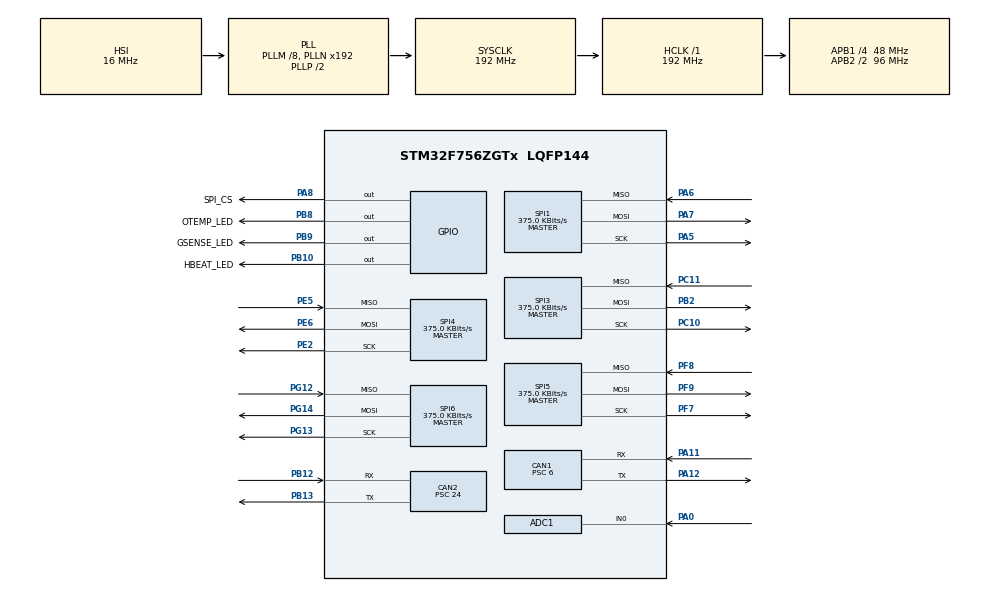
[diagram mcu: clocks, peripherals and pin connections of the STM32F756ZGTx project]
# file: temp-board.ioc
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ADC1.Channel-0\#ChannelRegularConversion=ADC_CHANNEL_0
ADC1.NbrOfConversionFlag=1
ADC1.Rank-0\#ChannelRegularConversion=1
ADC1.SamplingTime-0\#ChannelRegularConversion=ADC_SAMPLETIME_3CYCLES
ADC1.master=1
CAN1.ABOM=ENABLE
CAN1.AWUM=ENABLE
CAN1.BS1=CAN_BS1_6TQ
CAN1.BS2=CAN_BS2_1TQ
CAN1.CalculateBaudRate=1000000
CAN1.CalculateTimeBit=1000
CAN1.CalculateTimeQuantum=125.0
CAN1.Mode=CAN_MODE_LOOPBACK
CAN1.Prescaler=6
CAN2.ABOM=ENABLE
CAN2.AWUM=ENABLE
CAN2.BS1=CAN_BS1_6TQ
CAN2.BS2=CAN_BS2_1TQ
CAN2.CalculateBaudRate=250000
CAN2.CalculateTimeBit=4000
CAN2.CalculateTimeQuantum=500.0
CAN2.Prescaler=24
FREERTOS.Tasks01=taskMain_Loop,0,256,task_main_loop,Default,NULL,Dynamic,NULL,NULL;taskGCAN_TX,0,256,task_gcan_tx,Default,NULL,Dynamic,NULL,NULL;task_GCAN_RX,0,256,task_gcan_rx,Default,NULL,Dynamic,NULL,NULL
FREERTOS.configMINIMAL_STACK_SIZE=256
Mcu.Family=STM32F7
Mcu.Name=STM32F756ZGTx
Mcu.Package=LQFP144
NVIC.CAN1_RX0_IRQn=true\:5\:0\:false\:false\:true\:true\:true\:true\:true
NVIC.CAN1_RX1_IRQn=true\:5\:0\:false\:false\:true\:true\:true\:true\:true
NVIC.CAN1_TX_IRQn=true\:5\:0\:false\:false\:true\:true\:true\:true\:true
NVIC.PriorityGroup=NVIC_PRIORITYGROUP_4
NVIC.SPI1_IRQn=true\:5\:0\:false\:false\:true\:true\:true\:true\:true
NVIC.SPI3_IRQn=true\:5\:0\:false\:false\:true\:true\:true\:true\:true
NVIC.SPI4_IRQn=true\:5\:0\:false\:false\:true\:true\:true\:true\:true
NVIC.SPI5_IRQn=true\:5\:0\:false\:false\:true\:true\:true\:true\:true
NVIC.SPI6_IRQn=true\:5\:0\:false\:false\:true\:true\:true\:true\:true
NVIC.TIM6_DAC_IRQn=true\:0\:0\:false\:false\:true\:false\:false\:true\:true
NVIC.TIM8_TRG_COM_TIM14_IRQn=true\:5\:0\:false\:false\:true\:true\:true\:true\:true
NVIC.TimeBase=TIM6_DAC_IRQn
NVIC.TimeBaseIP=TIM6
PA0/WKUP.Signal=ADCx_IN0
PA11.Mode=CAN_Activate
PA11.Signal=CAN1_RX
PA12.Mode=CAN_Activate
PA12.Signal=CAN1_TX
PA5.Mode=Full_Duplex_Master
PA5.Signal=SPI1_SCK
PA6.Mode=Full_Duplex_Master
PA6.Signal=SPI1_MISO
PA7.Mode=Full_Duplex_Master
PA7.Signal=SPI1_MOSI
PA8.GPIO_Label=SPI_CS
PA8.Signal=GPIO_Output
PB10.GPIO_Label=HBEAT_LED
PB10.Signal=GPIO_Output
PB12.Mode=CAN_Activate
PB12.Signal=CAN2_RX
PB13.Mode=CAN_Activate
PB13.Signal=CAN2_TX
PB2.Mode=Full_Duplex_Master
PB2.Signal=SPI3_MOSI
PB8.GPIO_Label=OTEMP_LED
PB8.Signal=GPIO_Output
PB9.GPIO_Label=GSENSE_LED
PB9.Signal=GPIO_Output
PC10.Mode=Full_Duplex_Master
PC10.Signal=SPI3_SCK
PC11.Mode=Full_Duplex_Master
PC11.Signal=SPI3_MISO
PE2.Mode=Full_Duplex_Master
PE2.Signal=SPI4_SCK
PE5.Mode=Full_Duplex_Master
PE5.Signal=SPI4_MISO
PE6.Mode=Full_Duplex_Master
PE6.Signal=SPI4_MOSI
PF7.Mode=Full_Duplex_Master
PF7.Signal=SPI5_SCK
PF8.Mode=Full_Duplex_Master
PF8.Signal=SPI5_MISO
PF9.Mode=Full_Duplex_Master
PF9.Signal=SPI5_MOSI
PG12.Mode=Full_Duplex_Master
PG12.Signal=SPI6_MISO
PG13.Mode=Full_Duplex_Master
PG13.Signal=SPI6_SCK
PG14.Mode=Full_Duplex_Master
PG14.Signal=SPI6_MOSI
ProjectManager.HeapSize=0x200
ProjectManager.StackSize=0x400
ProjectManager.TargetToolchain=STM32CubeIDE
RCC.AHBFreq_Value=192000000
RCC.APB1CLKDivider=RCC_HCLK_DIV4
RCC.APB1Freq_Value=48000000
RCC.APB1TimFreq_Value=96000000
RCC.APB2CLKDivider=RCC_HCLK_DIV2
RCC.APB2Freq_Value=96000000
RCC.APB2TimFreq_Value=192000000
RCC.CortexFreq_Value=192000000
RCC.HCLKFreq_Value=192000000
RCC.HSE_VALUE=25000000
RCC.HSI_VALUE=16000000
RCC.LSE_VALUE=32768
RCC.PLLM=8
RCC.SYSCLKFreq_VALUE=192000000
RCC.SYSCLKSource=RCC_SYSCLKSOURCE_PLLCLK
RCC.USBFreq_Value=192000000
RCC.VCOOutputFreq_Value=384000000
SH.ADCx_IN0.0=ADC1_IN0,IN0
SPI1.BaudRatePrescaler=SPI_BAUDRATEPRESCALER_256
SPI1.CalculateBaudRate=375.0 KBits/s
SPI1.DataSize=SPI_DATASIZE_16BIT
SPI1.Direction=SPI_DIRECTION_2LINES
SPI1.FirstBit=SPI_FIRSTBIT_MSB
SPI1.Mode=SPI_MODE_MASTER
SPI1.NSSPMode=SPI_NSS_PULSE_DISABLE
SPI1.VirtualType=VM_MASTER
SPI3.BaudRatePrescaler=SPI_BAUDRATEPRESCALER_128
SPI3.CalculateBaudRate=375.0 KBits/s
SPI3.DataSize=SPI_DATASIZE_16BIT
SPI3.Direction=SPI_DIRECTION_2LINES
SPI3.Mode=SPI_MODE_MASTER
SPI3.NSSPMode=SPI_NSS_PULSE_DISABLE
SPI3.VirtualType=VM_MASTER
SPI4.BaudRatePrescaler=SPI_BAUDRATEPRESCALER_256
SPI4.CalculateBaudRate=375.0 KBits/s
SPI4.DataSize=SPI_DATASIZE_16BIT
SPI4.Direction=SPI_DIRECTION_2LINES
SPI4.Mode=SPI_MODE_MASTER
SPI4.NSSPMode=SPI_NSS_PULSE_DISABLE
SPI4.VirtualType=VM_MASTER
SPI5.BaudRatePrescaler=SPI_BAUDRATEPRESCALER_256
SPI5.CalculateBaudRate=375.0 KBits/s
SPI5.DataSize=SPI_DATASIZE_16BIT
SPI5.Direction=SPI_DIRECTION_2LINES
SPI5.Mode=SPI_MODE_MASTER
SPI5.NSSPMode=SPI_NSS_PULSE_DISABLE
SPI5.VirtualType=VM_MASTER
SPI6.BaudRatePrescaler=SPI_BAUDRATEPRESCALER_256
SPI6.CalculateBaudRate=375.0 KBits/s
SPI6.DataSize=SPI_DATASIZE_16BIT
SPI6.Direction=SPI_DIRECTION_2LINES
SPI6.Mode=SPI_MODE_MASTER
SPI6.NSSPMode=SPI_NSS_PULSE_DISABLE
SPI6.VirtualType=VM_MASTER
VP_FREERTOS_VS_CMSIS_V1.Mode=CMSIS_V1
VP_SYS_VS_tim6.Mode=TIM6
VP_TIM14_VS_ClockSourceINT.Mode=Enable_Timer
board=custom

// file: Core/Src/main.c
/* USER CODE BEGIN Header */
/**
  ******************************************************************************
  * @file           : main.c
  * @brief          : Main program body
  ******************************************************************************
  * @attention
  *
  * <h2><center>&copy; Copyright (c) 2021 STMicroelectronics.
  * All rights reserved.</center></h2>
  *
  * This software component is licensed by ST under BSD 3-Clause license,
  * the "License"; You may not use this file except in compliance with the
  * License. You may obtain a copy of the License at:
  *                        opensource.org/licenses/BSD-3-Clause
  *
  ******************************************************************************
  */
/* USER CODE END Header */
#include "main.h"
#include "cmsis_os.h"

/* USER CODE BEGIN Includes */
#include "temp_board_main.h"
#include "spi_adc.h"
#include "DAM.h"
/* USER CODE END Includes */

ADC_HandleTypeDef hadc1;

CAN_HandleTypeDef hcan1;
CAN_HandleTypeDef hcan2;

SPI_HandleTypeDef hspi1;
SPI_HandleTypeDef hspi3;
SPI_HandleTypeDef hspi4;
SPI_HandleTypeDef hspi5;
SPI_HandleTypeDef hspi6;

TIM_HandleTypeDef htim14;

osThreadId taskMain_LoopHandle;
osThreadId taskGCAN_TXHandle;
osThreadId task_GCAN_RXHandle;

void SystemClock_Config(void);
static void MX_GPIO_Init(void);
static void MX_CAN1_Init(void);
static void MX_CAN2_Init(void);
static void MX_SPI1_Init(void);
static void MX_SPI3_Init(void);
static void MX_SPI4_Init(void);
static void MX_SPI5_Init(void);
static void MX_SPI6_Init(void);
static void MX_TIM14_Init(void);
static void MX_ADC1_Init(void);
void task_main_loop(void const * argument);
void task_gcan_tx(void const * argument);
void task_gcan_rx(void const * argument);

int main(void)
{

  /* MCU Configuration--------------------------------------------------------*/

  /* Reset of all peripherals, Initializes the Flash interface and the Systick. */
  HAL_Init();

  /* Configure the system clock */
  SystemClock_Config();

  /* Initialize all configured peripherals */
  MX_GPIO_Init();
  MX_CAN1_Init();
  MX_CAN2_Init();
  MX_SPI1_Init();
  MX_SPI3_Init();
  MX_SPI4_Init();
  MX_SPI5_Init();
  MX_SPI6_Init();
  MX_TIM14_Init();
  MX_ADC1_Init();
  /* USER CODE BEGIN 2 */

  init(&hcan1, &hcan2);

  /* USER CODE END 2 */

  /* Create the thread(s) */
  /* definition and creation of taskMain_Loop */
  osThreadDef(taskMain_Loop, task_main_loop, osPriorityNormal, 0, 256);
  taskMain_LoopHandle = osThreadCreate(osThread(taskMain_Loop), NULL);

  /* definition and creation of taskGCAN_TX */
  osThreadDef(taskGCAN_TX, task_gcan_tx, osPriorityNormal, 0, 256);
  taskGCAN_TXHandle = osThreadCreate(osThread(taskGCAN_TX), NULL);

  /* definition and creation of task_GCAN_RX */
  osThreadDef(task_GCAN_RX, task_gcan_rx, osPriorityNormal, 0, 256);
  task_GCAN_RXHandle = osThreadCreate(osThread(task_GCAN_RX), NULL);

  /* Start scheduler */
  osKernelStart();

  /* We should never get here as control is now taken by the scheduler */
  /* Infinite loop */
  while (1)
  {

  }
}

void SystemClock_Config(void)
{
  RCC_OscInitTypeDef RCC_OscInitStruct = {0};
  RCC_ClkInitTypeDef RCC_ClkInitStruct = {0};

  /** Configure the main internal regulator output voltage
  */
  __HAL_RCC_PWR_CLK_ENABLE();
  __HAL_PWR_VOLTAGESCALING_CONFIG(PWR_REGULATOR_VOLTAGE_SCALE1);
  /** Initializes the RCC Oscillators according to the specified parameters
  * in the RCC_OscInitTypeDef structure.
  */
  RCC_OscInitStruct.OscillatorType = RCC_OSCILLATORTYPE_HSI;
  RCC_OscInitStruct.HSIState = RCC_HSI_ON;
  RCC_OscInitStruct.HSICalibrationValue = RCC_HSICALIBRATION_DEFAULT;
  RCC_OscInitStruct.PLL.PLLState = RCC_PLL_ON;
  RCC_OscInitStruct.PLL.PLLSource = RCC_PLLSOURCE_HSI;
  RCC_OscInitStruct.PLL.PLLM = 8;
  RCC_OscInitStruct.PLL.PLLN = 192;
  RCC_OscInitStruct.PLL.PLLP = RCC_PLLP_DIV2;
  RCC_OscInitStruct.PLL.PLLQ = 2;
  if (HAL_RCC_OscConfig(&RCC_OscInitStruct) != HAL_OK)
  {
    Error_Handler();
  }
  /** Activate the Over-Drive mode
  */
  if (HAL_PWREx_EnableOverDrive() != HAL_OK)
  {
    Error_Handler();
  }
  /** Initializes the CPU, AHB and APB buses clocks
  */
  RCC_ClkInitStruct.ClockType = RCC_CLOCKTYPE_HCLK|RCC_CLOCKTYPE_SYSCLK
                              |RCC_CLOCKTYPE_PCLK1|RCC_CLOCKTYPE_PCLK2;
  RCC_ClkInitStruct.SYSCLKSource = RCC_SYSCLKSOURCE_PLLCLK;
  RCC_ClkInitStruct.AHBCLKDivider = RCC_SYSCLK_DIV1;
  RCC_ClkInitStruct.APB1CLKDivider = RCC_HCLK_DIV4;
  RCC_ClkInitStruct.APB2CLKDivider = RCC_HCLK_DIV2;

  if (HAL_RCC_ClockConfig(&RCC_ClkInitStruct, FLASH_LATENCY_6) != HAL_OK)
  {
    Error_Handler();
  }
}

static void MX_ADC1_Init(void)
{

  ADC_ChannelConfTypeDef sConfig = {0};

  /** Configure the global features of the ADC (Clock, Resolution, Data Alignment and number of conversion)
  */
  hadc1.Instance = ADC1;
  hadc1.Init.ClockPrescaler = ADC_CLOCK_SYNC_PCLK_DIV4;
  hadc1.Init.Resolution = ADC_RESOLUTION_12B;
  hadc1.Init.ScanConvMode = ADC_SCAN_DISABLE;
  hadc1.Init.ContinuousConvMode = DISABLE;
  hadc1.Init.DiscontinuousConvMode = DISABLE;
  hadc1.Init.ExternalTrigConvEdge = ADC_EXTERNALTRIGCONVEDGE_NONE;
  hadc1.Init.ExternalTrigConv = ADC_SOFTWARE_START;
  hadc1.Init.DataAlign = ADC_DATAALIGN_RIGHT;
  hadc1.Init.NbrOfConversion = 1;
  hadc1.Init.DMAContinuousRequests = DISABLE;
  hadc1.Init.EOCSelection = ADC_EOC_SINGLE_CONV;
  if (HAL_ADC_Init(&hadc1) != HAL_OK)
  {
    Error_Handler();
  }
  /** Configure for the selected ADC regular channel its corresponding rank in the sequencer and its sample time.
  */
  sConfig.Channel = ADC_CHANNEL_0;
  sConfig.Rank = ADC_REGULAR_RANK_1;
  sConfig.SamplingTime = ADC_SAMPLETIME_3CYCLES;
  if (HAL_ADC_ConfigChannel(&hadc1, &sConfig) != HAL_OK)
  {
    Error_Handler();
  }

}

static void MX_CAN1_Init(void)
{

  hcan1.Instance = CAN1;
  hcan1.Init.Prescaler = 6;
  hcan1.Init.Mode = CAN_MODE_LOOPBACK;
  hcan1.Init.SyncJumpWidth = CAN_SJW_1TQ;
  hcan1.Init.TimeSeg1 = CAN_BS1_6TQ;
  hcan1.Init.TimeSeg2 = CAN_BS2_1TQ;
  hcan1.Init.TimeTriggeredMode = DISABLE;
  hcan1.Init.AutoBusOff = ENABLE;
  hcan1.Init.AutoWakeUp = ENABLE;
  hcan1.Init.AutoRetransmission = DISABLE;
  hcan1.Init.ReceiveFifoLocked = DISABLE;
  hcan1.Init.TransmitFifoPriority = DISABLE;
  if (HAL_CAN_Init(&hcan1) != HAL_OK)
  {
    Error_Handler();
  }

}

static void MX_CAN2_Init(void)
{

  hcan2.Instance = CAN2;
  hcan2.Init.Prescaler = 24;
  hcan2.Init.Mode = CAN_MODE_NORMAL;
  hcan2.Init.SyncJumpWidth = CAN_SJW_1TQ;
  hcan2.Init.TimeSeg1 = CAN_BS1_6TQ;
  hcan2.Init.TimeSeg2 = CAN_BS2_1TQ;
  hcan2.Init.TimeTriggeredMode = DISABLE;
  hcan2.Init.AutoBusOff = ENABLE;
  hcan2.Init.AutoWakeUp = ENABLE;
  hcan2.Init.AutoRetransmission = DISABLE;
  hcan2.Init.ReceiveFifoLocked = DISABLE;
  hcan2.Init.TransmitFifoPriority = DISABLE;
  if (HAL_CAN_Init(&hcan2) != HAL_OK)
  {
    Error_Handler();
  }

}

static void MX_SPI1_Init(void)
{

  /* SPI1 parameter configuration*/
  hspi1.Instance = SPI1;
  hspi1.Init.Mode = SPI_MODE_MASTER;
  hspi1.Init.Direction = SPI_DIRECTION_2LINES;
  hspi1.Init.DataSize = SPI_DATASIZE_16BIT;
  hspi1.Init.CLKPolarity = SPI_POLARITY_LOW;
  hspi1.Init.CLKPhase = SPI_PHASE_1EDGE;
  hspi1.Init.NSS = SPI_NSS_SOFT;
  hspi1.Init.BaudRatePrescaler = SPI_BAUDRATEPRESCALER_256;
  hspi1.Init.FirstBit = SPI_FIRSTBIT_MSB;
  hspi1.Init.TIMode = SPI_TIMODE_DISABLE;
  hspi1.Init.CRCCalculation = SPI_CRCCALCULATION_DISABLE;
  hspi1.Init.CRCPolynomial = 7;
  hspi1.Init.CRCLength = SPI_CRC_LENGTH_DATASIZE;
  hspi1.Init.NSSPMode = SPI_NSS_PULSE_DISABLE;
  if (HAL_SPI_Init(&hspi1) != HAL_OK)
  {
    Error_Handler();
  }

}

static void MX_SPI3_Init(void)
{

  /* SPI3 parameter configuration*/
  hspi3.Instance = SPI3;
  hspi3.Init.Mode = SPI_MODE_MASTER;
  hspi3.Init.Direction = SPI_DIRECTION_2LINES;
  hspi3.Init.DataSize = SPI_DATASIZE_16BIT;
  hspi3.Init.CLKPolarity = SPI_POLARITY_LOW;
  hspi3.Init.CLKPhase = SPI_PHASE_1EDGE;
  hspi3.Init.NSS = SPI_NSS_SOFT;
  hspi3.Init.BaudRatePrescaler = SPI_BAUDRATEPRESCALER_128;
  hspi3.Init.FirstBit = SPI_FIRSTBIT_MSB;
  hspi3.Init.TIMode = SPI_TIMODE_DISABLE;
  hspi3.Init.CRCCalculation = SPI_CRCCALCULATION_DISABLE;
  hspi3.Init.CRCPolynomial = 7;
  hspi3.Init.CRCLength = SPI_CRC_LENGTH_DATASIZE;
  hspi3.Init.NSSPMode = SPI_NSS_PULSE_DISABLE;
  if (HAL_SPI_Init(&hspi3) != HAL_OK)
  {
    Error_Handler();
  }

}

static void MX_SPI4_Init(void)
{

  /* SPI4 parameter configuration*/
  hspi4.Instance = SPI4;
  hspi4.Init.Mode = SPI_MODE_MASTER;
  hspi4.Init.Direction = SPI_DIRECTION_2LINES;
  hspi4.Init.DataSize = SPI_DATASIZE_16BIT;
  hspi4.Init.CLKPolarity = SPI_POLARITY_LOW;
  hspi4.Init.CLKPhase = SPI_PHASE_1EDGE;
  hspi4.Init.NSS = SPI_NSS_SOFT;
  hspi4.Init.BaudRatePrescaler = SPI_BAUDRATEPRESCALER_256;
  hspi4.Init.FirstBit = SPI_FIRSTBIT_MSB;
  hspi4.Init.TIMode = SPI_TIMODE_DISABLE;
  hspi4.Init.CRCCalculation = SPI_CRCCALCULATION_DISABLE;
  hspi4.Init.CRCPolynomial = 7;
  hspi4.Init.CRCLength = SPI_CRC_LENGTH_DATASIZE;
  hspi4.Init.NSSPMode = SPI_NSS_PULSE_DISABLE;
  if (HAL_SPI_Init(&hspi4) != HAL_OK)
  {
    Error_Handler();
  }

}

static void MX_SPI5_Init(void)
{

  /* SPI5 parameter configuration*/
  hspi5.Instance = SPI5;
  hspi5.Init.Mode = SPI_MODE_MASTER;
  hspi5.Init.Direction = SPI_DIRECTION_2LINES;
  hspi5.Init.DataSize = SPI_DATASIZE_16BIT;
  hspi5.Init.CLKPolarity = SPI_POLARITY_LOW;
  hspi5.Init.CLKPhase = SPI_PHASE_1EDGE;
  hspi5.Init.NSS = SPI_NSS_SOFT;
  hspi5.Init.BaudRatePrescaler = SPI_BAUDRATEPRESCALER_256;
  hspi5.Init.FirstBit = SPI_FIRSTBIT_MSB;
  hspi5.Init.TIMode = SPI_TIMODE_DISABLE;
  hspi5.Init.CRCCalculation = SPI_CRCCALCULATION_DISABLE;
  hspi5.Init.CRCPolynomial = 7;
  hspi5.Init.CRCLength = SPI_CRC_LENGTH_DATASIZE;
  hspi5.Init.NSSPMode = SPI_NSS_PULSE_DISABLE;
  if (HAL_SPI_Init(&hspi5) != HAL_OK)
  {
    Error_Handler();
  }

}

static void MX_SPI6_Init(void)
{

  /* SPI6 parameter configuration*/
  hspi6.Instance = SPI6;
  hspi6.Init.Mode = SPI_MODE_MASTER;
  hspi6.Init.Direction = SPI_DIRECTION_2LINES;
  hspi6.Init.DataSize = SPI_DATASIZE_16BIT;
  hspi6.Init.CLKPolarity = SPI_POLARITY_LOW;
  hspi6.Init.CLKPhase = SPI_PHASE_1EDGE;
  hspi6.Init.NSS = SPI_NSS_SOFT;
  hspi6.Init.BaudRatePrescaler = SPI_BAUDRATEPRESCALER_256;
  hspi6.Init.FirstBit = SPI_FIRSTBIT_MSB;
  hspi6.Init.TIMode = SPI_TIMODE_DISABLE;
  hspi6.Init.CRCCalculation = SPI_CRCCALCULATION_DISABLE;
  hspi6.Init.CRCPolynomial = 7;
  hspi6.Init.CRCLength = SPI_CRC_LENGTH_DATASIZE;
  hspi6.Init.NSSPMode = SPI_NSS_PULSE_DISABLE;
  if (HAL_SPI_Init(&hspi6) != HAL_OK)
  {
    Error_Handler();
  }

}

static void MX_TIM14_Init(void)
{

  htim14.Instance = TIM14;
  htim14.Init.Prescaler = 0;
  htim14.Init.CounterMode = TIM_COUNTERMODE_UP;
  htim14.Init.Period = 65535;
  htim14.Init.ClockDivision = TIM_CLOCKDIVISION_DIV1;
  htim14.Init.AutoReloadPreload = TIM_AUTORELOAD_PRELOAD_DISABLE;
  if (HAL_TIM_Base_Init(&htim14) != HAL_OK)
  {
    Error_Handler();
  }

}

static void MX_GPIO_Init(void)
{
  GPIO_InitTypeDef GPIO_InitStruct = {0};

  /* GPIO Ports Clock Enable */
  __HAL_RCC_GPIOE_CLK_ENABLE();
  __HAL_RCC_GPIOF_CLK_ENABLE();
  __HAL_RCC_GPIOA_CLK_ENABLE();
  __HAL_RCC_GPIOB_CLK_ENABLE();
  __HAL_RCC_GPIOC_CLK_ENABLE();
  __HAL_RCC_GPIOG_CLK_ENABLE();

  /*Configure GPIO pin Output Level */
  HAL_GPIO_WritePin(GPIOB, HBEAT_LED_Pin|OTEMP_LED_Pin|GSENSE_LED_Pin, GPIO_PIN_RESET);

  /*Configure GPIO pin Output Level */
  HAL_GPIO_WritePin(SPI_CS_GPIO_Port, SPI_CS_Pin, GPIO_PIN_RESET);

  /*Configure GPIO pins : HBEAT_LED_Pin OTEMP_LED_Pin GSENSE_LED_Pin */
  GPIO_InitStruct.Pin = HBEAT_LED_Pin|OTEMP_LED_Pin|GSENSE_LED_Pin;
  GPIO_InitStruct.Mode = GPIO_MODE_OUTPUT_PP;
  GPIO_InitStruct.Pull = GPIO_NOPULL;
  GPIO_InitStruct.Speed = GPIO_SPEED_FREQ_LOW;
  HAL_GPIO_Init(GPIOB, &GPIO_InitStruct);

  /*Configure GPIO pin : SPI_CS_Pin */
  GPIO_InitStruct.Pin = SPI_CS_Pin;
  GPIO_InitStruct.Mode = GPIO_MODE_OUTPUT_PP;
  GPIO_InitStruct.Pull = GPIO_NOPULL;
  GPIO_InitStruct.Speed = GPIO_SPEED_FREQ_LOW;
  HAL_GPIO_Init(SPI_CS_GPIO_Port, &GPIO_InitStruct);

}

void task_main_loop(void const * argument)
{
  /* USER CODE BEGIN 5 */
  /* Infinite loop */
  for(;;)
  {
	  main_loop();
    osDelay(10);
  }
  /* USER CODE END 5 */
}

void task_gcan_tx(void const * argument)
{
  /* USER CODE BEGIN task_gcan_tx */
  /* Infinite loop */
  for(;;)
  {
	  gopherCAN_tx_service_task();
    osDelay(1);
  }
  /* USER CODE END task_gcan_tx */
}

void task_gcan_rx(void const * argument)
{
  /* USER CODE BEGIN task_gcan_rx */
  /* Infinite loop */
  for(;;)
  {
	  gopherCAN_rx_buffer_service_task();
    osDelay(1);
  }
  /* USER CODE END task_gcan_rx */
}

 /**
  * @brief  Period elapsed callback in non blocking mode
  * @note   This function is called  when TIM6 interrupt took place, inside
  * HAL_TIM_IRQHandler(). It makes a direct call to HAL_IncTick() to increment
  * a global variable "uwTick" used as application time base.
  * @param  htim : TIM handle
  * @retval None
  */
void HAL_TIM_PeriodElapsedCallback(TIM_HandleTypeDef *htim)
{
  if (htim->Instance == TIM6) {
    HAL_IncTick();
  }
  /* USER CODE BEGIN Callback 1 */

  if (htim->Instance == TIM14)
  {
	  spi_timer_interrupt();
  }

  /* USER CODE END Callback 1 */
}

void Error_Handler(void)
{
  __disable_irq();
  while (1)
  {
  }
}

/************************ (C) COPYRIGHT STMicroelectronics *****END OF FILE****/
